VERSION ""

NS_ :

BS_:

BU_:

BO_ 256 msg1: 8 Vector__XXX
 SG_ v1 : 0|32@1+ (1,0) [-3.4e+38|3.4e+38] "" Vector__XXX
 SG_ v2 : 32|32@1+ (1,0) [-3.4e+38|3.4e+38] "" Vector__XXX

BO_ 257 msg2: 8 Vector__XXX
 SG_ v3 : 0|32@1+ (1,0) [-3.4e+38|3.4e+38] "" Vector__XXX
 SG_ v4 : 32|32@1+ (1,0) [-3.4e+38|3.4e+38] "" Vector__XXX

BO_ 257 state: 1 Vector__XXX
 SG_ system_state : 0|8@1+ (1,0) [0|255] "" Vector__XXX

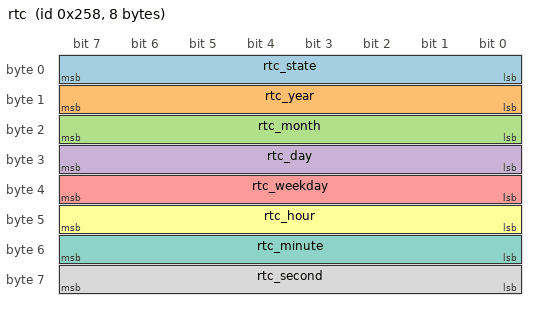
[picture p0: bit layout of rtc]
BO_ 600 rtc: 8 Vector__XXX
 SG_ rtc_state : 0|8@1+ (1,0) [0|255] "" Vector__XXX
 SG_ rtc_year : 8|8@1+ (1,2000) [2000|2099] "" Vector__XXX
 SG_ rtc_month : 16|8@1+ (1,0) [1|12] "" Vector__XXX
 SG_ rtc_day : 24|8@1+ (1,0) [1|31] "" Vector__XXX
 SG_ rtc_weekday : 32|8@1+ (1,0) [1|7] "" Vector__XXX
 SG_ rtc_hour : 40|8@1+ (1,0) [0|23] "" Vector__XXX
 SG_ rtc_minute : 48|8@1+ (1,0) [0|59] "" Vector__XXX
 SG_ rtc_second : 56|8@1+ (1,0) [0|59] "" Vector__XXX

CM_ BO_ 257 "State machine info";
BA_DEF_  "BusType" STRING ;
BA_DEF_DEF_  "BusType" "CAN";
